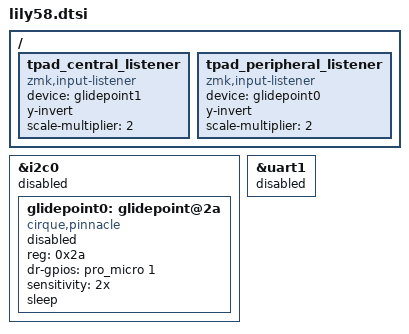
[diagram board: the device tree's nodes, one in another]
&i2c0 {
    status = "disabled";
    glidepoint0: glidepoint@2a {
        compatible = "cirque,pinnacle";
        reg = <0x2a>;
        status = "disabled";
        dr-gpios = <&pro_micro 1  (GPIO_ACTIVE_HIGH)>; // 006
        // dr-gpios = <&gpio1 1 (GPIO_ACTIVE_HIGH)>; // P1.01
        sensitivity = "2x";
        sleep;
        //no-taps;
    };

};

&uart1 {
    status = "disabled";
};


/ {
	/* assign `input-listener` to all pointing devices */
	/* &glidepoint0 on central, &glidepoint1 on peripheral */
    tpad_central_listener {
        compatible = "zmk,input-listener";
        device = <&glidepoint1>;
        //xy-swap;
        y-invert;
        //x-invert;
        scale-multiplier = <2>;
	};

    tpad_peripheral_listener {
        compatible = "zmk,input-listener";
        device = <&glidepoint0>;
        //xy-swap;
        y-invert;
        //x-invert;
        scale-multiplier = <2>;
    };

};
